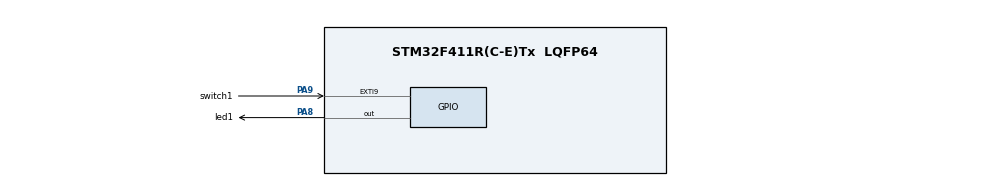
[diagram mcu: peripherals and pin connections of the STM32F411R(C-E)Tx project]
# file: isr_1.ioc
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Mcu.Family=STM32F4
Mcu.Name=STM32F411R(C-E)Tx
Mcu.Package=LQFP64
NVIC.EXTI9_5_IRQn=true\:0\:0\:false\:false\:true\:true\:true\:true
NVIC.PriorityGroup=NVIC_PRIORITYGROUP_0
PA8.GPIO_Label=led1
PA8.Signal=GPIO_Output
PA9.GPIO_Label=switch1
PA9.GPIO_ModeDefaultEXTI=GPIO_MODE_IT_RISING_FALLING
PA9.GPIO_PuPd=GPIO_PULLUP
PA9.Signal=GPXTI9
PH0\ -\ OSC_IN.Mode=HSE-External-Clock-Source
PH0\ -\ OSC_IN.Signal=RCC_OSC_IN
PH1\ -\ OSC_OUT.Mode=HSE-External-Clock-Source
PH1\ -\ OSC_OUT.Signal=RCC_OSC_OUT
ProjectManager.HeapSize=0x200
ProjectManager.StackSize=0x400
ProjectManager.TargetToolchain=STM32CubeIDE
RCC.48MHZClocksFreq_Value=84000000
RCC.AHBFreq_Value=84000000
RCC.APB1CLKDivider=RCC_HCLK_DIV2
RCC.APB1Freq_Value=42000000
RCC.APB1TimFreq_Value=84000000
RCC.APB2Freq_Value=84000000
RCC.APB2TimFreq_Value=84000000
RCC.CortexFreq_Value=84000000
RCC.FLatency-AdvancedSettings=FLASH_LATENCY_2
RCC.HCLKFreq_Value=84000000
RCC.HSE_VALUE=8000000
RCC.HSI_VALUE=16000000
RCC.LSE_VALUE=32768
RCC.PLLN=336
RCC.PLLP=RCC_PLLP_DIV4
RCC.SYSCLKFreq_VALUE=84000000
RCC.SYSCLKSource=RCC_SYSCLKSOURCE_PLLCLK
RCC.VCOOutputFreq_Value=336000000
board=NUCLEO-F411RE

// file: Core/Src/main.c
/* USER CODE BEGIN Header */
/**
  ******************************************************************************
  * @file           : main.c
  * @brief          : Main program body
  ******************************************************************************
  * @attention
  *
  * Copyright (c) 2024 STMicroelectronics.
  * All rights reserved.
  *
  * This software is licensed under terms that can be found in the LICENSE file
  * in the root directory of this software component.
  * If no LICENSE file comes with this software, it is provided AS-IS.
  *
  ******************************************************************************
  */
/* USER CODE END Header */
#include "main.h"

/* USER CODE BEGIN PD */
#define LED_TOGGLE_DELAY 100 // Delay for LED toggle test
#define DEBOUNCE_DELAY 50    // Debounce delay for button press
/* USER CODE END PD */

/* USER CODE BEGIN PV */
static uint8_t button_pressed = 0; // Flag to track button state
/* USER CODE END PV */

void SystemClock_Config(void);
static void MX_GPIO_Init(void);

int main(void)
{

  /* MCU Configuration--------------------------------------------------------*/

  /* Reset of all peripherals, Initializes the Flash interface and the Systick. */
  HAL_Init();

  /* Configure the system clock */

  /* Initialize all configured peripherals */
  MX_GPIO_Init();
  /* USER CODE BEGIN 2 */

  // Blink LED initially to confirm GPIO is working
  for (int i = 0; i < 3; i++) {
      HAL_GPIO_TogglePin(GPIOA, led1_Pin);
      HAL_Delay(LED_TOGGLE_DELAY);
  }

  /* USER CODE END 2 */

  /* Infinite loop */
  while (1)
  {

    /* USER CODE BEGIN 3 */
    if (button_pressed) {
      HAL_GPIO_TogglePin(GPIOA, led1_Pin);
      button_pressed = 0; // Reset flag
    }
  }
  /* USER CODE END 3 */
}

static void MX_GPIO_Init(void)
{
  GPIO_InitTypeDef GPIO_InitStruct = {0};

  /* GPIO Ports Clock Enable */
  __HAL_RCC_GPIOC_CLK_ENABLE();
  __HAL_RCC_GPIOH_CLK_ENABLE();
  __HAL_RCC_GPIOA_CLK_ENABLE();
  __HAL_RCC_GPIOB_CLK_ENABLE();

  /*Configure GPIO pin Output Level */
  HAL_GPIO_WritePin(GPIOA, led1_Pin, GPIO_PIN_RESET);

  /*Configure GPIO pin : switch1_Pin */
  GPIO_InitStruct.Pin = switch1_Pin;
  GPIO_InitStruct.Mode = GPIO_MODE_IT_FALLING;  // Detect button press only
  GPIO_InitStruct.Pull = GPIO_PULLUP;
  HAL_GPIO_Init(switch1_GPIO_Port, &GPIO_InitStruct);

  /*Configure GPIO pin : led1_Pin */
  GPIO_InitStruct.Pin = led1_Pin;
  GPIO_InitStruct.Mode = GPIO_MODE_OUTPUT_PP;
  GPIO_InitStruct.Pull = GPIO_NOPULL;
  GPIO_InitStruct.Speed = GPIO_SPEED_FREQ_LOW;
  HAL_GPIO_Init(GPIOA, &GPIO_InitStruct);

  /* EXTI interrupt init*/
  HAL_NVIC_SetPriority(EXTI9_5_IRQn, 0, 0);
  HAL_NVIC_EnableIRQ(EXTI9_5_IRQn);
}

/* USER CODE BEGIN 4 */
void HAL_GPIO_EXTI_Callback(uint16_t GPIO_Pin)
{
  if (GPIO_Pin == switch1_Pin)
  {
    HAL_Delay(DEBOUNCE_DELAY);  // Debounce delay
    if (HAL_GPIO_ReadPin(switch1_GPIO_Port, switch1_Pin) == GPIO_PIN_RESET) // Confirm button press
    {
      button_pressed = 1; // Set flag to toggle LED in main loop
    }
  }
}
/* USER CODE END 4 */
